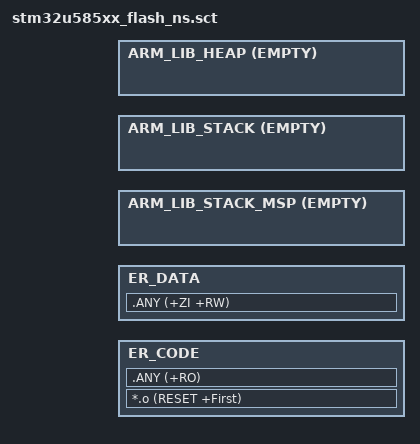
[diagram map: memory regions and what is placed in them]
#! armclang --target=arm-arm-none-eabi -march=armv8-m.main -E -xc

/*
 * Copyright (c) 2017-2018 ARM Limited
 *
 * Licensed under the Apache License, Version 2.0 (the "License");
 * you may not use this file except in compliance with the License.
 * You may obtain a copy of the License at
 *
 *     http://www.apache.org/licenses/LICENSE-2.0
 *
 * Unless required by applicable law or agreed to in writing, software
 * distributed under the License is distributed on an "AS IS" BASIS,
 * WITHOUT WARRANTIES OR CONDITIONS OF ANY KIND, either express or implied.
 * See the License for the specific language governing permissions and
 * limitations under the License.
 */

#include "region_defs.h"

LR_CODE LOADER_NS_CODE_START {
    ER_CODE (LOADER_NS_CODE_START) (LOADER_NS_CODE_SIZE){
        *.o (RESET +First)
        .ANY (+RO)
    }

   
    ER_DATA (LOADER_NS_DATA_START ) (LOADER_NS_DATA_SIZE) {
        .ANY (+ZI +RW)
    }
    /* MSP */
    ARM_LIB_STACK_MSP +0 ALIGN 32 EMPTY LOADER_NS_MSP_STACK_SIZE {
    }

    /* PSP */
    ARM_LIB_STACK +0 ALIGN 32 EMPTY LOADER_NS_PSP_STACK_SIZE {
    }

    ARM_LIB_HEAP +0 ALIGN 8 EMPTY LOADER_NS_HEAP_SIZE {
    }
}

